# ExynosT100 register map
Vendor: SAMSUNG System LSI; Series: ARMCM4F; File version: 0.1
CPU: CM4 r1p0, little endian, MPU, FPU, 3 interrupt priority bits
Registers are 32-bit, read-write, reset 0x0 unless marked. A register's access mark holds for its fields unless they carry their own. Offsets are from the block's base; [hi:lo] are bit positions; 'fields as' and 'values as' point back to an identical list.

## RTC — Real time clock
Base 0x400A0A00
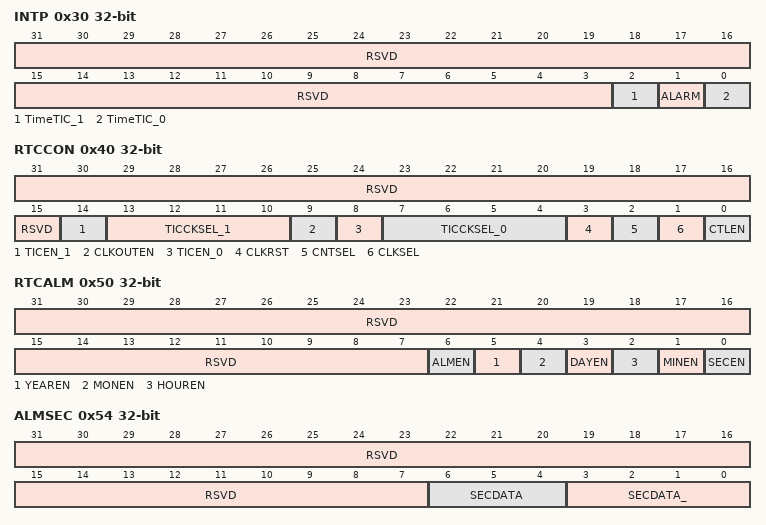
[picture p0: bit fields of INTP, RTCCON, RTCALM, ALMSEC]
0x30 INTP — Interrupt Pending Register interrupt pending bit 0 = Interrupt did not occur 1 = Interrupt occurred
  [31:3] RSVD ro, [2] TimeTIC_1, [1] ALARM, [0] TimeTIC_0
0x40 RTCCON — RTC Control Register
  [31:15] RSVD ro
  [14] TICEN_1 — Enables the tick timer 0 = Disable 1 = Enable
  [13:10] TICCKSEL_1 — Tick timer sub-clock selection sub-clock frequency = RTC clock source frequency / 2 ^ (TICKSEL_1)
  [9] CLKOUTEN — Enables RTC clock output on XRTCCLKO pad 0 = Disable 1 = Enable
  [8] TICEN_0 — Enables tick timer 0 = Disables tick timer and resets tick count 1 = Enables tick timer
  [7:4] TICCKSEL_0 — Tick timer sub-clock selection sub-clock frequency = RTC clock source frequency / 2 ^ (TICKSEL_1)
  [3] CLKRST — Enables RTC clock and tick timer clock reset 0 = Enables RTC clock (1 Hz clock) and tick timer clock 1 = Disables RTC clock and tick timer clock NOTE: When CTLEN is enabled, CLKRST affects RTC. NOTE : If you set tick timer count as 0 (TICCKSEL=4'b0000), it is always on regardless of RTCCON[3]
  [2] CNTSEL — Selects the BCD count 0 = Merge BCD counters 1 = Reserved (separate BCD counters) NOTE: When CTLEN is enabled, CNTSEL affects RTC.
  [1] CLKSEL — BCD clock select 0 = XTAL 1/215 divided clock 1 = Reserved (XTAL clock only for test) NOTE: When CTLEN is enabled, CLKSEL affects RTC.
  [0] CTLEN — Enables RTC control 0 = Disables RTC control 1 = Enables RTC control NOTE: 1. When CTLEN is enabled, you can change the BCD time count settings, 215 clock divider reset settings, BCD counter selection, and BCD clock selection. 2. RTC power consumption increases when CTLEN is 1. This bit should be 0 to achieve low power consumption when RTC control is not required.
0x44 TICCNT_0 — Tick Time Count Register
  [31:0] TICK_TIME_COUNT — 32-bit tick time count value NOTE: This value must be greater than 3.
0x48 TICCNT_1 — Tick Time Count Register
  fields as TICCNT_0
0x50 RTCALM — RTC Alarm Control Register 0 = disable 1 = enable
  [31:7] RSVD ro, [6] ALMEN, [5] YEAREN, [4] MONEN, [3] DAYEN, [2] HOUREN, [1] MINEN, [0] SECEN
0x54 ALMSEC — Alarm Second Data Register
  [31:7] RSVD ro
  [6:4] SECDATA — BCD value for an alarm second 0 to 5
  [3:0] SECDATA_ — 0 to 9
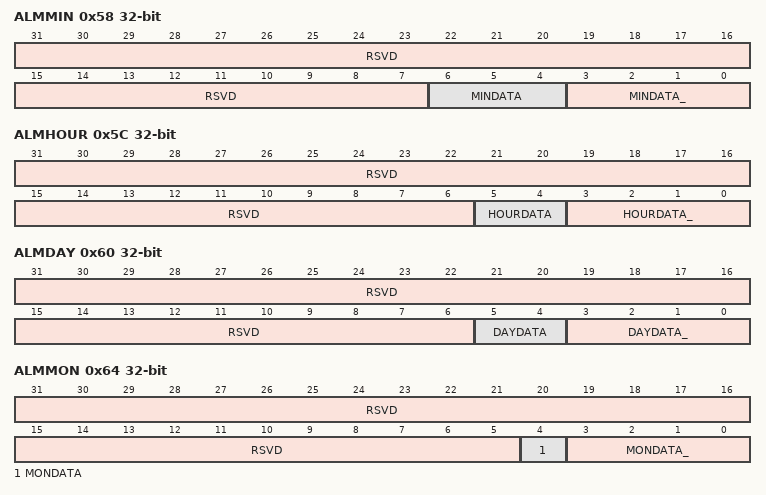
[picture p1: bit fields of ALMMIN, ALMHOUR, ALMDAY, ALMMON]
0x58 ALMMIN — Alarm Minute Data Register
  [31:7] RSVD ro
  [6:4] MINDATA — BCD value for alarm minute 0 to 5
  [3:0] MINDATA_ — 0 to 9
0x5C ALMHOUR — Alarm Hour Data Register
  [31:6] RSVD ro
  [5:4] HOURDATA — BCD value for alarm hour 0 to 2
  [3:0] HOURDATA_ — 0 to 9
0x60 ALMDAY — Alarm Day Data Register
  [31:6] RSVD ro
  [5:4] DAYDATA — BCD value for alarm day, from 0 to 28/ 29/ 30/ 31 0 to 3
  [3:0] DAYDATA_ — 0 to 9
0x64 ALMMON — Alarm Month Data Register
  [31:5] RSVD ro
  [4] MONDATA — BCD value for alarm month 0 to 1
  [3:0] MONDATA_ — 0 to 9
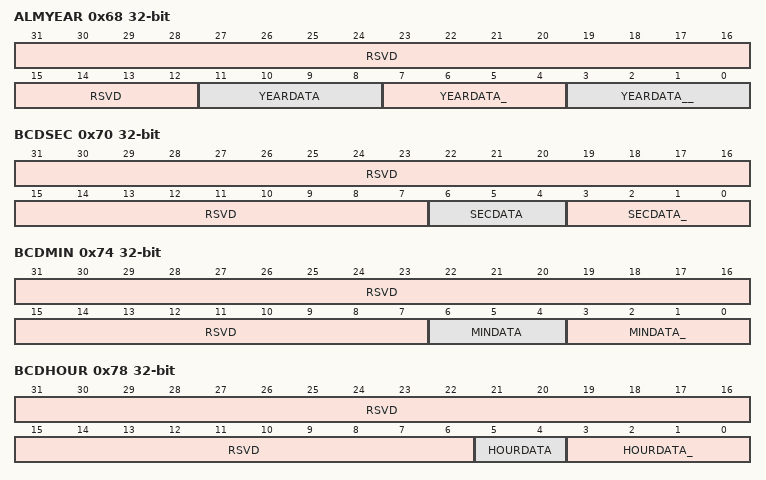
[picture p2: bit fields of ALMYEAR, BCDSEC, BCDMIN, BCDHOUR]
0x68 ALMYEAR — Alarm Year Data Register
  [31:12] RSVD ro
  [11:8] YEARDATA — BCD value for alarm year 0 to 9
  [7:4] YEARDATA_ — 0 to 9
  [3:0] YEARDATA__ — 0 to 9
0x70 BCDSEC — BCD Second Register
  [31:7] RSVD ro
  [6:4] SECDATA — BCD value for second 0 to 5
  [3:0] SECDATA_ — 0 to 9
0x74 BCDMIN — BCD Minute Register
  [31:7] RSVD ro
  [6:4] MINDATA — BCD value for minute 0 to 5
  [3:0] MINDATA_ — 0 to 9
0x78 BCDHOUR
  [31:6] RSVD ro
  [5:4] HOURDATA — BCD value for hour 0 to 2
  [3:0] HOURDATA_ — 0 to 9
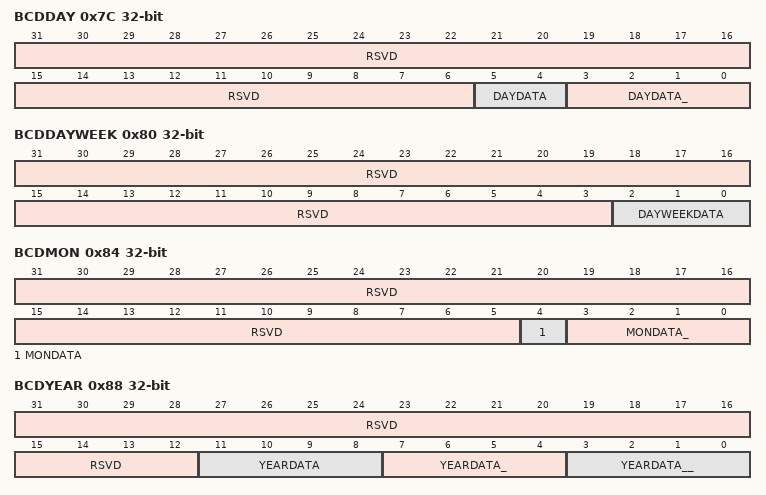
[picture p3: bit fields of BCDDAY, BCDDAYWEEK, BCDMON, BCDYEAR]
0x7C BCDDAY
  [31:6] RSVD ro
  [5:4] DAYDATA — BCD value for day 0 to 3
  [3:0] DAYDATA_ — 0 to 9
0x80 BCDDAYWEEK — BCD Day of the Week Register
  [31:3] RSVD ro
  [2:0] DAYWEEKDATA — BCD value for a day of the week 1 to 7
0x84 BCDMON — BCD Month Register
  [31:5] RSVD ro
  [4] MONDATA — BCD value for month 0 to 1
  [3:0] MONDATA_ — 0 to 9
0x88 BCDYEAR
  [31:12] RSVD ro
  [11:8] YEARDATA — BCD value for Year 0 to 9
  [7:4] YEARDATA_ — 0 to 9
  [3:0] YEARDATA__ — 0 to 9
0x90 CURTICCNT_0 — Current Tick Time Counter Register
  [31:0] Tickcounterobservation ro — Current tick count value
0x94 CURTICCNT_1 — Current Tick Time Counter Register
  [31:0] Tickcounterobservation ro — Current tick count value
